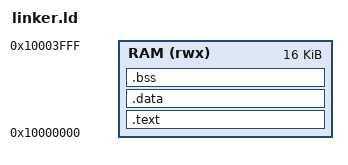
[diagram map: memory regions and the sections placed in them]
ENTRY(_start)

MEMORY
{
    RAM (rwx) : ORIGIN = 0x10000000, LENGTH = 16K
}

SECTIONS
{
    .text :
    {
        KEEP(*(.text.start))
        *(.text*)
        *(.rodata*)
    } > RAM

    .data :
    {
        . = ALIGN(4);
        *(.data*)
        *(.sdata*)
    } > RAM

    .bss (NOLOAD) :
    {
        . = ALIGN(4);
        _sbss = .;
        *(.bss*)
        *(.sbss*)
        *(COMMON)
        . = ALIGN(4);
        _ebss = .;
    } > RAM

    _end = .;
    ASSERT(_end <= ORIGIN(RAM) + LENGTH(RAM), "USB-MIDI firmware exceeds 16 KiB")
}

